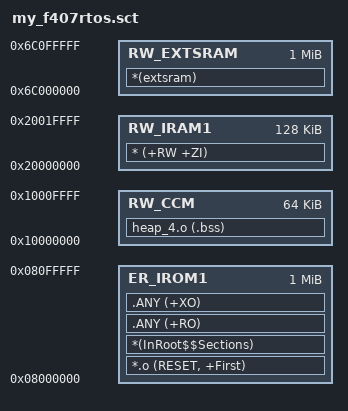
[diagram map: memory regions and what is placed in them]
LR_IROM1 0x08000000 0x00100000  {  ; Flash 1MB
  ER_IROM1 0x08000000 0x00100000  {  ; Code/RO
    *.o (RESET, +First)
    *(InRoot$$Sections)
    .ANY (+RO)
    .ANY (+XO)
  }

  ; 可选：CCM RAM（Core-Coupled Memory, 64KB，地址 0x10000000..0x1000FFFF）
  ; 仅供CPU访问，DMA/SDIO/I2S/FSMC等外设无法访问！不要放需要DMA的缓冲
  RW_CCM   0x10000000 0x00010000  {
    ; 优先放入较大ZI数据以释放 0x20000000 段容量
    heap_4.o               (.bss)      ; FreeRTOS heap 数组在 .bss（ZI）
    ;*(ccmram)                          ; 允许通过 __attribute__((section("ccmram"))) 精细放入（若有对象使用则启用）
    ;lv_port_disp_template.o(+ZI)
    ;lv_port_disp_template.o(.bss)
    ; 可按需选择性放入：算法局部大数组、非DMA缓冲、临时工作区等
    ; 例如：;some_algo.o(+ZI)
  }

  ; 外部 SRAM（FSMC Bank4/NE4）—优先于内部SRAM通配放置，避免被 * (+RW +ZI) 捕获
  RW_EXTSRAM 0x6C000000 0x00100000  {
    *(extsram)                          ; 仅通过显式节选择放入，避免误将关键缓冲落到外部SRAM
    ;mp3Player.o              (.bss)     ; 若包含I2S DMA缓冲，请保持在内部SRAM
  }

  ; 内部 SRAM（STM32F407: 0x20000000 连续可用 128KB = SRAM1(112KB)+SRAM2(16KB)）
  ; 注意：另有 64KB CCM 在 0x10000000，非与 0x20000000 连续，需单独建区
  RW_IRAM1 0x20000000 0x00020000  {  ; 128KB @0x20000000..0x2001FFFF
    * (+RW +ZI)
  }

  ; 可选：NOINIT（保留内容），如需大工作缓冲且不想上电被清零
  ;RW_EXTSRAM_NOINIT 0x6CF00000 0x00010000 UNINIT  {
  ;  mp3Player.o(.bss)
  ;}
}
